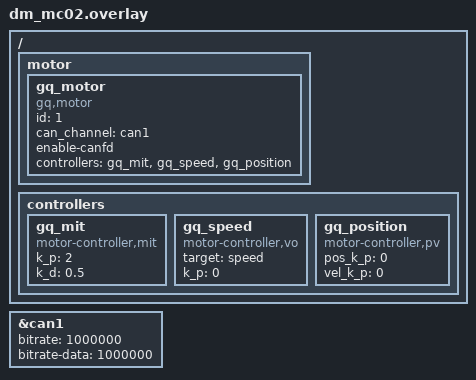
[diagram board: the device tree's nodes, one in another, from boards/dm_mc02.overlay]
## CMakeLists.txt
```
# Copyright (c) 2026 ttwards <12411711@mail.sustech.edu.cn>
# SPDX-License-Identifier: Apache-2.0

cmake_minimum_required(VERSION 3.20.0)

find_package(Zephyr REQUIRED HINTS $ENV{ZEPHYR_BASE})
project(gq_motor_demo)

target_sources(app PRIVATE src/main.c)
```

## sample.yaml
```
# Copyright (c) 2026 ttwards <12411711@mail.sustech.edu.cn>
# SPDX-License-Identifier: Apache-2.0

sample:
  name: Gaoqing motor demo
tests:
  sample.motor.gq:
    tags:
      - motor
      - can
    platform_allow:
      - dm_mc02
      - robomaster_board_c
    integration_platforms:
      - dm_mc02
      - robomaster_board_c
    harness: console
    harness_config:
      type: one_line
      regex:
        - "Gaoqing motor demo started"
```

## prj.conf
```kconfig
# Gaoqing motor demo common configuration.

CONFIG_MAIN_THREAD_PRIORITY=7
CONFIG_SYSTEM_WORKQUEUE_STACK_SIZE=2048

CONFIG_CONSOLE=y
CONFIG_UART_CONSOLE=y
CONFIG_LOG=y
CONFIG_LOG_BACKEND_UART=y
CONFIG_CBPRINTF_FP_SUPPORT=y

CONFIG_MOTOR=y
CONFIG_MOTOR_GQ=y

CONFIG_CAN=y
CONFIG_CAN_INIT_PRIORITY=80
```

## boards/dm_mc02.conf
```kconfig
# dm_mc02 uses STM32H7 FDCAN for this sample.
CONFIG_CAN_FD_MODE=y
```

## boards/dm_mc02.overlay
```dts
/ {
	motor {
		gq_motor: gq_motor {
			compatible = "gq,motor";
			status = "okay";
			id = <1>;
			can_channel = <&can1>;
			enable-canfd;
			controllers = <&gq_mit &gq_speed &gq_position>;
		};
	};

	controllers {
		gq_mit: gq_mit {
			compatible = "motor-controller,mit";
			k_p = "2";
			k_d = "0.5";
		};

		gq_speed: gq_speed {
			compatible = "motor-controller,vo";
			target = "speed";
			k_p = "0";
		};

		gq_position: gq_position {
			compatible = "motor-controller,pv";
			pos_k_p = "0";
			vel_k_p = "0";
		};
	};
};

&can1 {
	bitrate = <1000000>;
	bitrate-data = <1000000>;
};
```

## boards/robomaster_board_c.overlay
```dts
/ {
	motor {
		gq_motor: gq_motor {
			compatible = "gq,motor";
			status = "okay";
			id = <1>;
			can_channel = <&can1>;
			controllers = <&gq_mit &gq_speed &gq_position>;
		};
	};

	controllers {
		gq_mit: gq_mit {
			compatible = "motor-controller,mit";
			k_p = "2";
			k_d = "0.5";
		};

		gq_speed: gq_speed {
			compatible = "motor-controller,vo";
			target = "speed";
			k_p = "0";
		};

		gq_position: gq_position {
			compatible = "motor-controller,pv";
			pos_k_p = "0";
			vel_k_p = "0";
		};
	};
};
```

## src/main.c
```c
/*
 * Copyright (c) 2026 ttwards <12411711@mail.sustech.edu.cn>
 *
 * SPDX-License-Identifier: Apache-2.0
 */

#include <errno.h>

#include <zephyr/device.h>
#include <zephyr/drivers/motor.h>
#include <zephyr/kernel.h>
#include <zephyr/logging/log.h>

LOG_MODULE_REGISTER(gq_motor_demo, LOG_LEVEL_INF);

#define GQ_MOTOR_NODE DT_PATH(motor, gq_motor)

BUILD_ASSERT(DT_NODE_HAS_STATUS(GQ_MOTOR_NODE, okay), "gq_motor node must be enabled");

static const struct device *const gq_motor = DEVICE_DT_GET(GQ_MOTOR_NODE);

static void log_motor_status(void)
{
	motor_status_t status = {0};
	int ret = motor_get(gq_motor, &status);

	if (ret < 0) {
		LOG_INF("status unavailable: %d", ret);
		return;
	}

	LOG_INF("status: angle %.1f deg, speed %.1f rpm, torque %.2f Nm, error %d",
		(double)status.angle, (double)status.rpm, (double)status.torque, status.error);
}

int main(void)
{
	LOG_INF("Gaoqing motor demo started");

	if (!device_is_ready(gq_motor)) {
		LOG_ERR("Gaoqing motor device is not ready");
		return -ENODEV;
	}

	motor_control(gq_motor, ENABLE_MOTOR);
	k_msleep(200);

	while (true) {
		LOG_INF("command: speed 60 rpm");
		motor_set_speed(gq_motor, 60.0f);
		k_msleep(1000);
		log_motor_status();

		LOG_INF("command: position 90 deg");
		motor_set_angle(gq_motor, 90.0f);
		k_msleep(1000);
		log_motor_status();

		LOG_INF("command: MIT hold near zero");
		motor_set_mit(gq_motor, 0.0f, 0.0f, 0.0f);
		k_msleep(1000);
		log_motor_status();
	}

	return 0;
}
```
